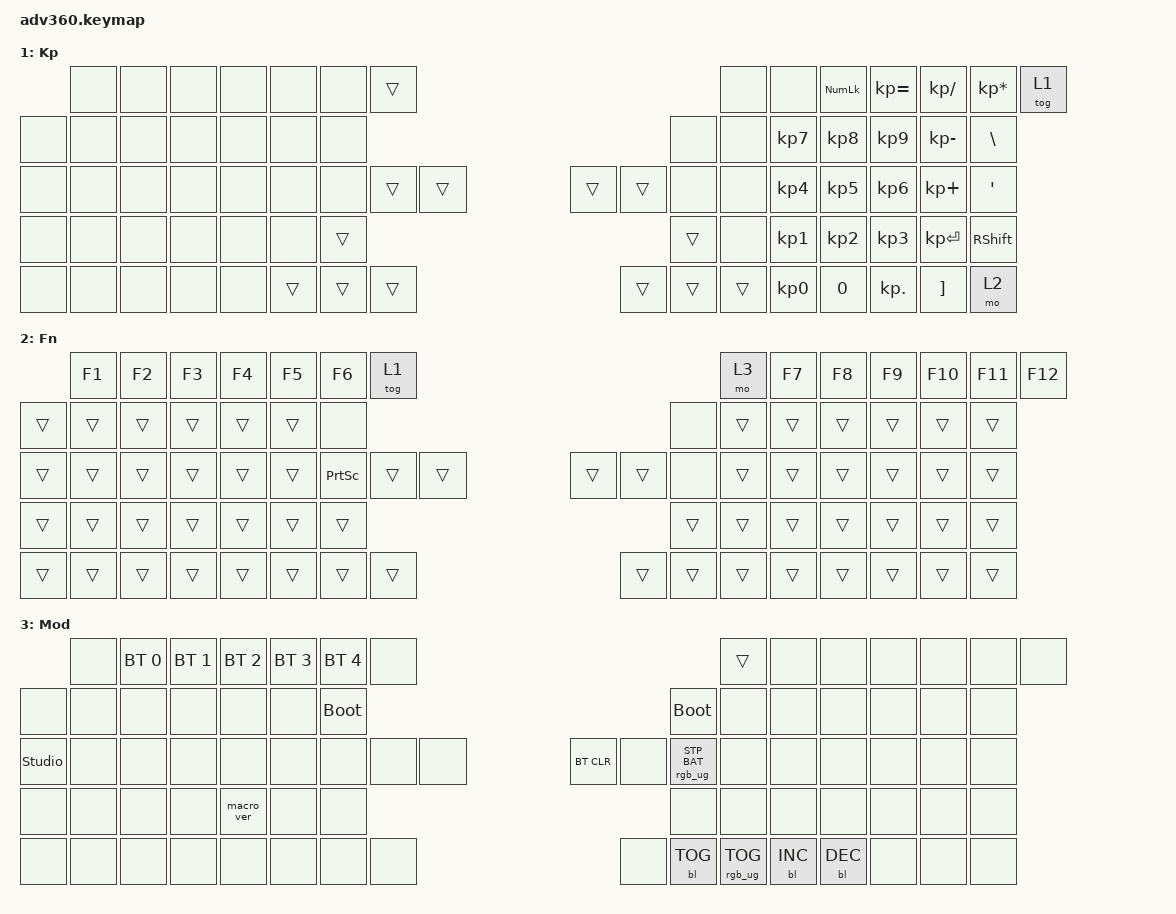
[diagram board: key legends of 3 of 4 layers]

/*
 * Copyright (c) 2020 The ZMK Contributors
 *
 * SPDX-License-Identifier: MIT
 */


/* THIS FILE WAS GENERATED!
 *
 * This file was generated automatically. You may or may not want to
 * edit it directly.
 */

#include <behaviors.dtsi>
#include <dt-bindings/zmk/keys.h>
#include <dt-bindings/zmk/bt.h>
#include <dt-bindings/zmk/rgb.h>
#include <dt-bindings/zmk/stp.h>
#include <dt-bindings/zmk/backlight.h>
#include <dt-bindings/zmk/pointing.h>

/ {
    behaviors {
      #include "macros.dtsi"
      #include "version.dtsi"

    hm: homerow_mods {
        compatible = "zmk,behavior-hold-tap";
        label = "HOMEROW_MODS";
        #binding-cells = <2>;
        tapping-term-ms = <200>;
        quick_tap_ms = <175>;
        flavor = "tap-preferred";
        bindings = <&kp>, <&kp>;
    };
  };

    keymap {
        compatible = "zmk,keymap";

    default_layer {
      display-name = "Base";
      bindings = <
           &kp ESC     &kp N1    &kp N2            &kp N3             &kp N4  &kp N5            &kp EQUAL                                                             &kp MINUS  &kp N6    &kp N7     &kp N8   &kp N9     &kp N0     &tog 1
   &kp TAB      &kp Q     &kp W             &kp E              &kp R   &kp T                &mo 2                                                                 &none   &kp Y     &kp U      &kp I    &kp O      &kp P   &kp BSLH
 &kp GRAVE      &kp A     &kp S             &kp D              &kp F   &kp G            &kp SPACE  &kp LCTRL     &mo 3                      &mo 3  &kp RCTRL   &kp BSPC   &kp H     &kp J      &kp K    &kp L   &kp SEMI    &kp SQT
 &kp LSHFT      &kp Z     &kp X             &kp C              &kp V   &kp B                                  &kp HOME                  &kp PG_UP                         &kp N     &kp M  &kp COMMA  &kp DOT   &kp FSLH  &kp RSHFT
 &kp LCTRL  &kp LMETA  &kp LALT  &kp LEFT_BRACKET  &kp RIGHT_BRACKET  
  >;
    };
    keypad {
      display-name = "Kp";
      bindings = <
         &none   &none   &none   &none   &none   &none            &trans                                                   &none   &none  &kp KP_NUM  &kp KP_EQUAL  &kp KP_DIVIDE  &kp KP_MULTIPLY     &tog 1
  &none   &none   &none   &none   &none   &none             &none                                                   &none   &none   &kp KP_N7     &kp KP_N8      &kp KP_N9     &kp KP_MINUS   &kp BSLH
  &none   &none   &none   &none   &none   &none             &none  &trans  &trans                  &trans  &trans   &none   &none   &kp KP_N4     &kp KP_N5      &kp KP_N6      &kp KP_PLUS    &kp SQT
  &none   &none   &none   &none   &none   &none                            &trans                  &trans                   &none   &kp KP_N1     &kp KP_N2      &kp KP_N3     &kp KP_ENTER  &kp RSHFT
  &none   &none   &none   &none   &none                    &trans  &trans  &trans                  &trans  &trans  &trans           &kp KP_N0        &kp N0     &kp KP_DOT         &kp RBKT      &mo 2
            >;
    };
    fn {
      display-name = "Fn";
      bindings = <
         &kp F1  &kp F2  &kp F3  &kp F4  &kp F5  &kp F6                     &tog 1                                                   &mo 3  &kp F7  &kp F8  &kp F9  &kp F10  &kp F11  &kp F12
 &trans  &trans  &trans  &trans  &trans  &trans                      &none                                                   &none  &trans  &trans  &trans   &trans   &trans   &trans
 &trans  &trans  &trans  &trans  &trans  &trans            &kp PRINTSCREEN  &trans  &trans                  &trans  &trans   &none  &trans  &trans  &trans   &trans   &trans   &trans
 &trans  &trans  &trans  &trans  &trans  &trans                                     &trans                  &trans                  &trans  &trans  &trans   &trans   &trans   &trans
 &trans  &trans  &trans  &trans  &trans                             &trans  &trans  &trans                  &trans  &trans  &trans          &trans  &trans   &trans   &trans   &trans
            >;
    };
    mod {
      display-name = "Mod";
      bindings = <
        &none  &bt BT_SEL 0  &bt BT_SEL 1  &bt BT_SEL 2  &bt BT_SEL 3  &bt BT_SEL 4                  &none                                                                          &trans   &none       &none       &none   &none   &none   &none
  &none          &none         &none         &none         &none         &none            &bootloader                                                                     &bootloader   &none       &none       &none   &none   &none   &none
  &studio_unlock &none         &none         &none         &none         &none                  &none   &none   &none                  &bt BT_CLR       &none  &rgb_ug STP_BAT   &none       &none       &none   &none   &none   &none
  &none          &none         &none         &none    &macro_ver         &none                                  &none                       &none                                       &none       &none       &none   &none   &none   &none
  &none          &none         &none         &none         &none                                &none   &none   &none                       &none  &bl BL_TOG         &rgb_ug RGB_TOG          &bl BL_INC  &bl BL_DEC   &none   &none   &none
            >;
    };
    extra1 { 
      display-name = "Red";    
      status = "reserved";
    };

    extra2 { 
      display-name = "Purple";    
      status = "reserved";
    };

    extra3 { 
      display-name = "Cyan";    
      status = "reserved";
    };

    extra4 { 
      display-name = "Yellow";    
      status = "reserved";
    };
  };
};
